# ESP32-C61 register map
Vendor: ESPRESSIF SYSTEMS (SHANGHAI) CO., LTD.; Series: ESP32 C-Series; File version: 1
CPU: RV32IMAC r0p0, little endian, no MPU, no FPU, 0 interrupt priority bits
Address unit: 32 bits
Registers are 32-bit, read-write, reset 0x0 unless marked. A register's access mark holds for its fields unless they carry their own. Offsets are from the block's base; [hi:lo] are bit positions; {n}, {i} and the like mark numbered series.

## TRACE — RISC-V Trace Encoder
Base 0x600C0000
0x00 MEM_START_ADDR — Memory start address
  [31:0] MEM_START_ADDR — Configures the start address of the trace memory
0x04 MEM_END_ADDR reset 0xFFFFFFFF — Memory end address
  [31:0] MEM_END_ADDR — Configures the end address of the trace memory.
0x08 MEM_CURRENT_ADDR ro — Memory current addr
  [31:0] MEM_CURRENT_ADDR — Represents the current memory address for writing.
0x0C MEM_ADDR_UPDATE wo — Memory address update
  [0] MEM_CURRENT_ADDR_UPDATE — Configures whether to update the value of \hyperref[fielddesc:TRACEMEMCURRENTADDR]{TRACE_MEM_CURRENT_ADDR} to \hyperref[fielddesc:TRACEMEMSTARTADDR]{TRACE_MEM_START_ADDR}.\\ 0: Not update\\ 1: Update\\
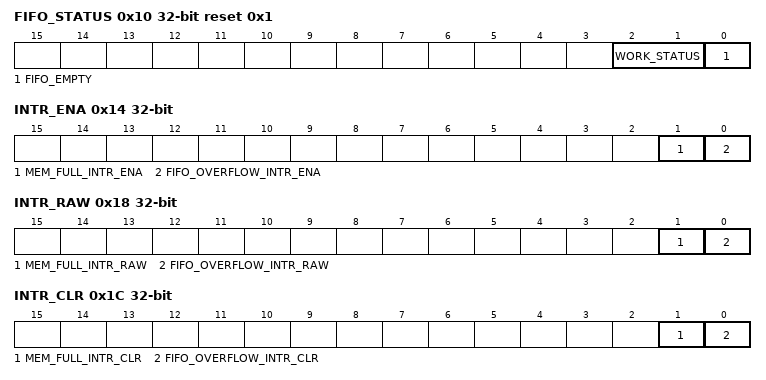
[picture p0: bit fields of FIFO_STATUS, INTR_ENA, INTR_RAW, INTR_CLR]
0x10 FIFO_STATUS ro reset 0x1
  [2:1] WORK_STATUS — Represent the state of the encoder: \\0: Idle state \\1: Working state\\ 2: Wait state becasue hart is halted or in reset \\3: Lost state\\
  [0] FIFO_EMPTY — Represent whether the FIFO is empty. \\1: Empty \\0: Not empty
0x14 INTR_ENA — Interrupt enable register
  [1] MEM_FULL_INTR_ENA — Write 1 to enable TRACE_MEM_FULL_INTR
  [0] FIFO_OVERFLOW_INTR_ENA — Write 1 to enable TRACE_FIFO_OVERFLOW_INTR
0x18 INTR_RAW ro — Interrupt raw status register
  [1] MEM_FULL_INTR_RAW — The raw interrupt status of TRACE_MEM_FULL_INTR
  [0] FIFO_OVERFLOW_INTR_RAW — The raw interrupt status of TRACE_FIFO_OVERFLOW_INTR.
0x1C INTR_CLR wo — Interrupt clear register
  [1] MEM_FULL_INTR_CLR — Write 1 to clear TRACE_MEM_FULL_INTR
  [0] FIFO_OVERFLOW_INTR_CLR — Write 1 to clear TRACE_FIFO_OVERFLOW_INTR
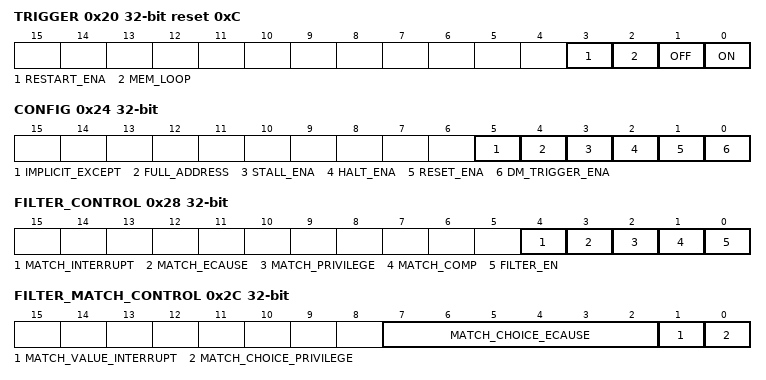
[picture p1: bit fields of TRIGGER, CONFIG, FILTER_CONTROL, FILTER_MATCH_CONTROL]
0x20 TRIGGER access per field reset 0xC — Trace enable register
  [3] RESTART_ENA rw — Configure whether or not enable automatic restart function for the encoder.\\0: Disable\\1: Enable\\
  [2] MEM_LOOP rw — Configure the memory writing mode. \\0: Non-loop mode. \\1: Loop mode\\
  [1] OFF wo — Configure whether to disable the encoder.\\0: Invalid \\1: Disable\\
  [0] ON wo — Configure whether to enable the encoder.\\0: Invalid \\1: Enable\\
0x24 CONFIG — trace configuration register
  [5] IMPLICIT_EXCEPT — Configure whether or not enabel implicit exception mode. When enabled,, do not sent exception address, only exception cause in exception packets.\\1: enabled\\0: disabled\\
  [4] FULL_ADDRESS — Configure the address mode.\\0: Delta address mode.\\1: Full address mode.\\
  [3] STALL_ENA — Configure whether to enable the stall signal. \\0: Disable.\\1: Enable\\
  [2] HALT_ENA — Configure whether to enable the halt signal. \\1: Disable\\1: Enable\\
  [1] RESET_ENA — Configure whether to reset, when enabeld, if cpu have reset, the encoder will output a packet to report the address of the last instruction, and upon reset deassertion, the encoder start again.\\0: Disable\\0: Enable\\
  [0] DM_TRIGGER_ENA — Configure whether to enable the trigger signal.\\0: Disable\\1:enable\\
0x28 FILTER_CONTROL
  [4] MATCH_INTERRUPT — Configure whether to enable the interrupt match mode. \\0: Disable \\1: Enable, start matching from a trap with the interrupt level codes specified by \hyperref[fielddesc:TRACEMATCHVALUEINTERRUPT]{TRACE_MATCH_VALUE_INTERRUPT}, and stop matching upon return from the 1st matching trap.
  [3] MATCH_ECAUSE — Configure whether to enable ecause match mode. \\0: Disable \\1: Enable, start matching from exception cause codes specified by \hyperref[fielddesc:TRACEMATCHCHOICEECAUSE]{TRACE_MATCH_CHOICE_ECAUSE}, and stop matching upon return from the 1st matching exception.
  [2] MATCH_PRIVILEGE — Configure whether to enable the privilege match mode. \\0: Disable \\1: Enable, match privilege levels specified by \hyperref[fielddesc:TRACEMATCHCHOICEPRIVILEGE]{TRACE_MATCH_CHOICE_PRIVILEGE}.
  [1] MATCH_COMP — Configure whether to enable the comparator match mode. \\0: Disable \\1: Enable, the comparator must be high in order for the filter to match
  [0] FILTER_EN — Configure whether to enable filtering. \\0: Disable, always match.\\ 1: Enable
0x2C FILTER_MATCH_CONTROL
  [7:2] MATCH_CHOICE_ECAUSE — Configures the ecause code for matching.
  [1] MATCH_VALUE_INTERRUPT — Configures the interrupt level for match. Valid only when when \hyperref[fielddesc:TRACEMATCHINTERRUPT]{TRACE_MATCH_INTERRUP} is set. \\0: itype=2. \\0: itype=2.
  [0] MATCH_CHOICE_PRIVILEGE — Configures the privilege level for matching. Valid only when \hyperref[fielddesc:TRACEMATCHPRIVILEGE]{TRACE_MATCH_PRIVILEGE} is set. \\0: User mode. \\1: Machine mode
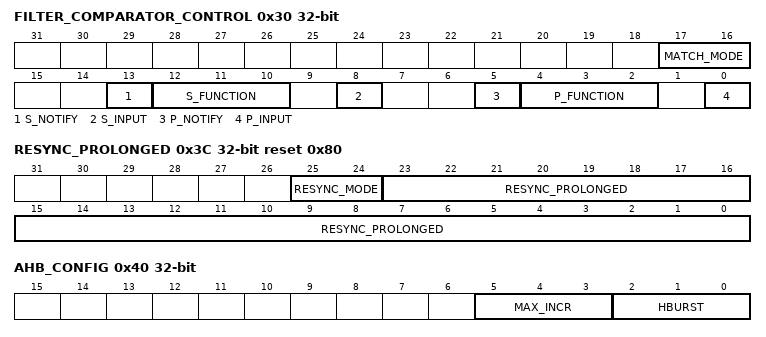
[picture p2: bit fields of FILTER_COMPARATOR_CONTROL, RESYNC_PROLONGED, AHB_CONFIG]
0x30 FILTER_COMPARATOR_CONTROL — filter comparator match control register
  [17:16] MATCH_MODE — Configures the comparator match mode: \\0: Only the primary comparator matches \\1: Both primary and secondary comparator matches(P\&\&S) \\ 2:Neither primary or secondary comparator matches !(P\&\&S) \\3: Start filtering when the primary comparator matches and stop filtering when the secondary comparator matches\\
  [13] S_NOTIFY — Generate a trace packet explicitly reporting the address that cause the secondary match
  [12:10] S_FUNCTION — Configures the function for the secondary comparator. \\0: Equal, \\1: Not equal, \\2: Less than, \\3: Less than or equal, \\4: Greater than, \\5: Greater than or equal, \\Other: Always match
  [8] S_INPUT — Configures the input of the secondary comparator for matching: \\0: iaddr \\1: tval\\
  [5] P_NOTIFY — Configure whether to explicitly report an instruction address matched against the primary comparator. \\0:Not report \\1:Report
  [4:2] P_FUNCTION — Configures the function for the primary comparator. \\0: Equal, \\1: Not equal, \\2: Less than, \\3: Less than or equal, \\4: Greater than, \\5: Greater than or equal, \\Other: Always match
  [0] P_INPUT — Configures the input of the primary comparator for matching: \\0: iaddr \\1: tval\\
0x34 FILTER_P_COMPARATOR_MATCH — primary comparator match value
  [31:0] P_MATCH — Configures the match value for the primary comparator
0x38 FILTER_S_COMPARATOR_MATCH — secondary comparator match value
  [31:0] S_MATCH — Configures the match value for the secondary comparator
0x3C RESYNC_PROLONGED reset 0x80 — Resync configuration register
  [25:24] RESYNC_MODE — Configures the synchronization mode: \\0: Disable the synchronization counter \\1: Invalid \\2: Synchronization counter counts by packet \\3: Synchronization counter counts by cycle\\
  [23:0] RESYNC_PROLONGED — Configures the threshold for synchronization counter
0x40 AHB_CONFIG
  [5:3] MAX_INCR — Configures the maximum burst length for INCR mode
  [2:0] HBURST — Configures the AHB burst mode. \\0: SIGNLE \\1: INCR(length not defined) \\2:INCR4 \\4:INCR8 \\Others:Invalid
0x44 CLOCK_GATE reset 0x1 — Clock gate control register
  [0] CLK_EN — Configures register clock gating. \\0: Support clock only when the application writes registers to save power. \\1:Always force the clock on for registers \\ This bit does't affect register access.
0x3FC DATE reset 0x2211300 — Version control register
  [27:0] DATE — Version control register.
